AUTOSAR XML (schema 4-0-3)
standard types defined: Boolean, UInt16, UInt32, UInt8
package /AUTOSAR_Platform/DataConstrs
  range DC_Boolean: raw 0..1
  range DC_UInt16: raw 0..65535
  range DC_UInt8: raw 0..255
package /PATAC/MSM/ComponentTypes
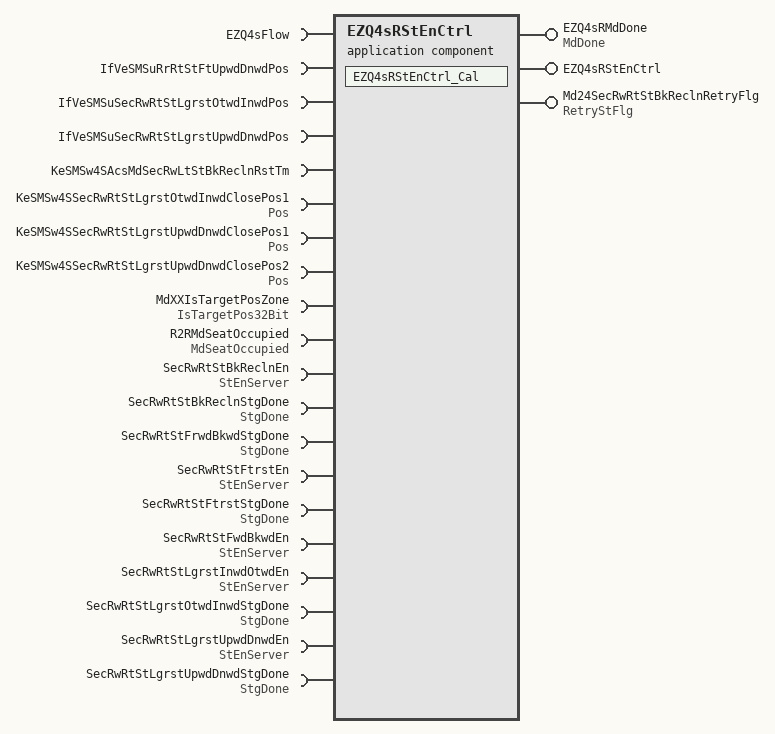
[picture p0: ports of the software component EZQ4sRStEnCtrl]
  application sw component type EZQ4sRStEnCtrl
    provide port EZQ4sRMdDone: nonqueued-sender-com-spec{data-element=MdDone/Val, init-value=0}, provided-interface=MdDone
    provide port EZQ4sRStEnCtrl: server-com-spec{operation=EZQ4sRStEnCtrl/Cal, queue-length=1}, provided-interface=EZQ4sRStEnCtrl
    provide port Md24SecRwRtStBkReclnRetryFlg: nonqueued-sender-com-spec=data-element=RetryStFlg/Val, provided-interface=RetryStFlg
    20 x require port:
      EZQ4sFlow: client-com-spec=EZQ4sFlow/Cal, required-interface=EZQ4sFlow
      IfVeSMSuRrRtStFtUpwdDnwdPos: nonqueued-receiver-com-spec{data-element=IfVeSMSuRrRtStFtUpwdDnwdPos/Val, filter=data-filter-type=ALWAYS, init-value=0}, required-interface=IfVeSMSuRrRtStFtUpwdDnwdPos
      IfVeSMSuSecRwRtStLgrstOtwdInwdPos: nonqueued-receiver-com-spec{data-element=IfVeSMSuSecRwRtStLgrstOtwdInwdPos/Val, filter=data-filter-type=ALWAYS, init-value=0}, required-interface=IfVeSMSuSecRwRtStLgrstOtwdInwdPos
      IfVeSMSuSecRwRtStLgrstUpwdDnwdPos: nonqueued-receiver-com-spec{data-element=IfVeSMSuSecRwRtStLgrstUpwdDnwdPos/Val, filter=data-filter-type=ALWAYS, init-value=0}, required-interface=IfVeSMSuSecRwRtStLgrstUpwdDnwdPos
      KeSMSw4SAcsMdSecRwLtStBkReclnRstTm: parameter-require-com-spec{init-value=1500, parameter=KeSMSw4SAcsMdSecRwLtStBkReclnRstTm/Val}, required-interface=KeSMSw4SAcsMdSecRwLtStBkReclnRstTm
      KeSMSw4SSecRwRtStLgrstOtwdInwdClosePos1: parameter-require-com-spec{init-value=0, parameter=Pos/Val}, required-interface=Pos
      KeSMSw4SSecRwRtStLgrstUpwdDnwdClosePos1: parameter-require-com-spec{init-value=0, parameter=Pos/Val}, required-interface=Pos
      KeSMSw4SSecRwRtStLgrstUpwdDnwdClosePos2: parameter-require-com-spec{init-value=0, parameter=Pos/Val}, required-interface=Pos
      MdXXIsTargetPosZone: nonqueued-receiver-com-spec{data-element=IsTargetPos32Bit/Val, filter=data-filter-type=ALWAYS, init-value=0}, required-interface=IsTargetPos32Bit
      R2RMdSeatOccupied: nonqueued-receiver-com-spec{data-element=MdSeatOccupied/Val, filter=data-filter-type=ALWAYS, init-value=0}, required-interface=MdSeatOccupied
      SecRwRtStBkReclnEn: required-com-specs=[Clear, Get, Set], required-interface=StEnServer
      SecRwRtStBkReclnStgDone: nonqueued-receiver-com-spec{data-element=StgDone/Val, filter=data-filter-type=ALWAYS, init-value=0}, required-interface=StgDone
      SecRwRtStFrwdBkwdStgDone: nonqueued-receiver-com-spec{data-element=StgDone/Val, filter=data-filter-type=ALWAYS, init-value=0}, required-interface=StgDone
      SecRwRtStFtrstEn: required-com-specs=[Clear, Get, Set], required-interface=StEnServer
      SecRwRtStFtrstStgDone: nonqueued-receiver-com-spec{data-element=StgDone/Val, filter=data-filter-type=ALWAYS, init-value=0}, required-interface=StgDone
      SecRwRtStFwdBkwdEn: required-com-specs=[Clear, Get, Set], required-interface=StEnServer
      SecRwRtStLgrstInwdOtwdEn: required-com-specs=[Clear, Get, Set], required-interface=StEnServer
      SecRwRtStLgrstOtwdInwdStgDone: nonqueued-receiver-com-spec{data-element=StgDone/Val, filter=data-filter-type=ALWAYS, init-value=0}, required-interface=StgDone
      SecRwRtStLgrstUpwdDnwdEn: required-com-specs=[Clear, Get, Set], required-interface=StEnServer
      SecRwRtStLgrstUpwdDnwdStgDone: nonqueued-receiver-com-spec{data-element=StgDone/Val, filter=data-filter-type=ALWAYS, init-value=0}, required-interface=StgDone
    behavior EZQ4sRStEnCtrl_InternalBehavior
      operation invoked event OIT_EZQ4sRStEnCtrl_Cal_EZQ4sRStEnCtrl_Cal: start-on-event=EZQ4sRStEnCtrl_Cal, operation=EZQ4sRStEnCtrl.Cal
      runnable EZQ4sRStEnCtrl_Cal
        data-receive-point-by-arguments:
          10 x access:
            REC_IfVeSMSuRrRtStFtUpwdDnwdPos_Val: accessed-variable=IfVeSMSuRrRtStFtUpwdDnwdPos.Val
            REC_IfVeSMSuSecRwRtStLgrstOtwdInwdPos_Val: accessed-variable=IfVeSMSuSecRwRtStLgrstOtwdInwdPos.Val
            REC_IfVeSMSuSecRwRtStLgrstUpwdDnwdPos_Val: accessed-variable=IfVeSMSuSecRwRtStLgrstUpwdDnwdPos.Val
            REC_MdXXIsTargetPosZone_Val: accessed-variable=MdXXIsTargetPosZone.Val
            REC_R2RMdSeatOccupied_Val: accessed-variable=R2RMdSeatOccupied.Val
            REC_SecRwRtStBkReclnStgDone_Val: accessed-variable=SecRwRtStBkReclnStgDone.Val
            REC_SecRwRtStFrwdBkwdStgDone_Val: accessed-variable=SecRwRtStFrwdBkwdStgDone.Val
            REC_SecRwRtStFtrstStgDone_Val: accessed-variable=SecRwRtStFtrstStgDone.Val
            REC_SecRwRtStLgrstOtwdInwdStgDone_Val: accessed-variable=SecRwRtStLgrstOtwdInwdStgDone.Val
            REC_SecRwRtStLgrstUpwdDnwdStgDone_Val: accessed-variable=SecRwRtStLgrstUpwdDnwdStgDone.Val
        data-send-points:
          access SEND_EZQ4sRMdDone_Val: accessed-variable=EZQ4sRMdDone.Val
          access SEND_Md24SecRwRtStBkReclnRetryFlg_Val: accessed-variable=Md24SecRwRtStBkReclnRetryFlg.Val
        4 x parameter access:
          PA_KeSMSw4SAcsMdSecRwLtStBkReclnRstTm_Val: accessed-parameter=KeSMSw4SAcsMdSecRwLtStBkReclnRstTm.Val
          PA_KeSMSw4SSecRwRtStLgrstOtwdInwdClosePos1_Val: accessed-parameter=KeSMSw4SSecRwRtStLgrstOtwdInwdClosePos1.Val
          PA_KeSMSw4SSecRwRtStLgrstUpwdDnwdClosePos1_Val: accessed-parameter=KeSMSw4SSecRwRtStLgrstUpwdDnwdClosePos1.Val
          PA_KeSMSw4SSecRwRtStLgrstUpwdDnwdClosePos2_Val: accessed-parameter=KeSMSw4SSecRwRtStLgrstUpwdDnwdClosePos2.Val
        11 x sync call, all with timeout=0:
          SC_EZQ4sFlow_Cal: operation=EZQ4sFlow.Cal
          SC_SecRwRtStBkReclnEn_Clear: operation=SecRwRtStBkReclnEn.Clear
          SC_SecRwRtStBkReclnEn_Set: operation=SecRwRtStBkReclnEn.Set
          SC_SecRwRtStFtrstEn_Clear: operation=SecRwRtStFtrstEn.Clear
          SC_SecRwRtStFtrstEn_Set: operation=SecRwRtStFtrstEn.Set
          SC_SecRwRtStFwdBkwdEn_Clear: operation=SecRwRtStFwdBkwdEn.Clear
          SC_SecRwRtStFwdBkwdEn_Set: operation=SecRwRtStFwdBkwdEn.Set
          SC_SecRwRtStLgrstInwdOtwdEn_Clear: operation=SecRwRtStLgrstInwdOtwdEn.Clear
          SC_SecRwRtStLgrstInwdOtwdEn_Set: operation=SecRwRtStLgrstInwdOtwdEn.Set
          SC_SecRwRtStLgrstUpwdDnwdEn_Clear: operation=SecRwRtStLgrstUpwdDnwdEn.Clear
          SC_SecRwRtStLgrstUpwdDnwdEn_Set: operation=SecRwRtStLgrstUpwdDnwdEn.Set
  swc implementation EZQ4sRStEnCtrl_Implementation: behavior=EZQ4sRStEnCtrl_InternalBehavior
    code-descriptors:
      code Default: artifact-descriptors=autosar-engineering-object={short-label=Default, category=SWSRC}
package /PATAC/MSM/ModeAdjust/CalPortInterface
  parameter interface KeSMSw4SAcsMdSecRwLtStBkReclnRstTm
    parameter data prototype Val: sw-calibration-access=READ-WRITE, type=UInt16
  parameter interface Pos
    parameter data prototype Val: sw-calibration-access=READ-WRITE, type=UInt16
package /PATAC/MSM/ModeAdjust/PortInterface
  client server interface EZQ4sFlow
    operation Cal
      20 x arg, all with server-argument-impl-policy=USE-ARGUMENT-TYPE:
        LgrstUpwdDnwdPos: type=UInt16, direction=IN
        LgrstOtwdInwdPos: type=UInt16, direction=IN
        FtUpwdDnwdPos: type=UInt16, direction=IN
        CloseDnwdPos1: type=UInt16, direction=IN
        CloseDnwdPos2: type=UInt16, direction=IN
        CloseOtwdPos1: type=UInt16, direction=IN
        LgrstInwdStgDone: type=Implementation/Boolean, direction=IN
        LgrstUpwdStgDone: type=Implementation/Boolean, direction=IN
        FtrstStgDone: type=Implementation/Boolean, direction=IN
        FrwdBkwdStgDone: type=DataTypes/Boolean, direction=IN
        BkReclnStgDone: type=DataTypes/Boolean, direction=IN
        StEmpty: type=DataTypes/Boolean, direction=IN
        Failflg: type=Implementation/Boolean, direction=OUT
        LgrstInwdOtwdEn: type=Implementation/Boolean, direction=OUT
        LgrstUpwdDnwdEn: type=Implementation/Boolean, direction=OUT
        FtrstEn: type=Implementation/Boolean, direction=OUT
        FrwdBkwdEn: type=DataTypes/Boolean, direction=OUT
        BkReclnEn: type=DataTypes/Boolean, direction=OUT
        WaitComplete: type=DataTypes/Boolean, direction=IN
        RetryStFlg: type=DataTypes/Boolean, direction=OUT
  client server interface EZQ4sRStEnCtrl
    operation Cal
      arg ResetCond: type=DataTypes/Boolean, direction=IN, server-argument-impl-policy=USE-ARGUMENT-TYPE
  client server interface StEnServer
    operation Clear
      arg data: type=UInt8, direction=IN, server-argument-impl-policy=USE-ARGUMENT-TYPE
    operation Get
      arg data: type=UInt32, direction=OUT, server-argument-impl-policy=USE-ARGUMENT-TYPE
    operation Set
      arg data: type=UInt8, direction=IN, server-argument-impl-policy=USE-ARGUMENT-TYPE
  5 x sender receiver interface:
    IsTargetPos32Bit: invalidation-policy{data-element=IsTargetPos32Bit/Val, handle-invalid=DONT-INVALIDATE}
      data Val: type=UInt32
    MdDone: invalidation-policy{data-element=MdDone/Val, handle-invalid=DONT-INVALIDATE}
      data Val: type=UInt8
    MdSeatOccupied: invalidation-policy{data-element=MdSeatOccupied/Val, handle-invalid=DONT-INVALIDATE}
      data Val: type=Implementation/Boolean
    RetryStFlg: invalidation-policy{data-element=RetryStFlg/Val, handle-invalid=DONT-INVALIDATE}
      data Val: type=Implementation/Boolean
    StgDone: invalidation-policy{data-element=StgDone/Val, handle-invalid=DONT-INVALIDATE}
      data Val: type=Implementation/Boolean
package /PATAC/MSM/PortInterfaces
  sender receiver interface IfVeSMSuRrRtStFtUpwdDnwdPos: invalidation-policy{data-element=IfVeSMSuRrRtStFtUpwdDnwdPos/Val, handle-invalid=DONT-INVALIDATE}
    data Val: type=UInt16
  sender receiver interface IfVeSMSuSecRwRtStLgrstOtwdInwdPos: invalidation-policy{data-element=IfVeSMSuSecRwRtStLgrstOtwdInwdPos/Val, handle-invalid=DONT-INVALIDATE}
    data Val: type=UInt16
  sender receiver interface IfVeSMSuSecRwRtStLgrstUpwdDnwdPos: invalidation-policy{data-element=IfVeSMSuSecRwRtStLgrstUpwdDnwdPos/Val, handle-invalid=DONT-INVALIDATE}
    data Val: type=UInt16
